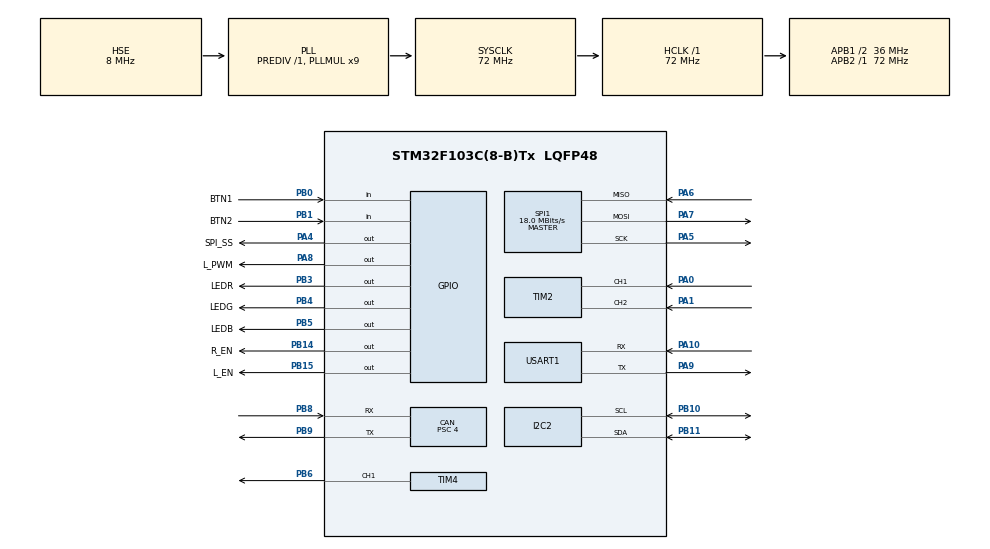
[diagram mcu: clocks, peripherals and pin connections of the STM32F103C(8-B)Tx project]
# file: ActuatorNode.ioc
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CAN.BS1=CAN_BS1_13TQ
CAN.BS2=CAN_BS2_4TQ
CAN.CalculateBaudRate=500000
CAN.CalculateTimeBit=2000
CAN.CalculateTimeQuantum=111.11111111111111
CAN.Prescaler=4
CAN.SJW=CAN_SJW_2TQ
Mcu.Family=STM32F1
Mcu.Name=STM32F103C(8-B)Tx
Mcu.Package=LQFP48
NVIC.CAN1_RX1_IRQn=true\:0\:0\:false\:false\:true\:true\:true\:true
NVIC.PriorityGroup=NVIC_PRIORITYGROUP_4
NVIC.USB_LP_CAN1_RX0_IRQn=true\:0\:0\:false\:false\:true\:true\:true\:true
PA0-WKUP.Signal=S_TIM2_CH1_ETR
PA1.Signal=S_TIM2_CH2
PA10.Mode=Asynchronous
PA10.Signal=USART1_RX
PA4.GPIO_Label=SPI_SS
PA4.Signal=GPIO_Output
PA5.Mode=Full_Duplex_Master
PA5.Signal=SPI1_SCK
PA6.Mode=Full_Duplex_Master
PA6.Signal=SPI1_MISO
PA7.Mode=Full_Duplex_Master
PA7.Signal=SPI1_MOSI
PA8.GPIO_Label=L_PWM
PA8.Signal=GPIO_Output
PA9.Mode=Asynchronous
PA9.Signal=USART1_TX
PB0.GPIO_Label=BTN1
PB0.Signal=GPIO_Input
PB1.GPIO_Label=BTN2
PB1.Signal=GPIO_Input
PB10.Mode=I2C
PB10.Signal=I2C2_SCL
PB11.Mode=I2C
PB11.Signal=I2C2_SDA
PB14.GPIO_Label=R_EN
PB14.Signal=GPIO_Output
PB15.GPIO_Label=L_EN
PB15.Signal=GPIO_Output
PB3.GPIO_Label=LEDR
PB3.PinState=GPIO_PIN_SET
PB3.Signal=GPIO_Output
PB4.GPIO_Label=LEDG
PB4.PinState=GPIO_PIN_SET
PB4.Signal=GPIO_Output
PB5.GPIO_Label=LEDB
PB5.PinState=GPIO_PIN_SET
PB5.Signal=GPIO_Output
PB6.Signal=S_TIM4_CH1
PB8.Mode=CAN_Activate
PB8.Signal=CAN_RX
PB9.Mode=CAN_Activate
PB9.Signal=CAN_TX
PD0-OSC_IN.Mode=HSE-External-Oscillator
PD0-OSC_IN.Signal=RCC_OSC_IN
PD1-OSC_OUT.Mode=HSE-External-Oscillator
PD1-OSC_OUT.Signal=RCC_OSC_OUT
ProjectManager.HeapSize=0x200
ProjectManager.StackSize=0x400
ProjectManager.TargetToolchain=STM32CubeIDE
RCC.AHBFreq_Value=72000000
RCC.APB1CLKDivider=RCC_HCLK_DIV2
RCC.APB1Freq_Value=36000000
RCC.APB1TimFreq_Value=72000000
RCC.APB2Freq_Value=72000000
RCC.APB2TimFreq_Value=72000000
RCC.HCLKFreq_Value=72000000
RCC.PLLMUL=RCC_PLL_MUL9
RCC.PLLSourceVirtual=RCC_PLLSOURCE_HSE
RCC.SYSCLKFreq_VALUE=72000000
RCC.SYSCLKSource=RCC_SYSCLKSOURCE_PLLCLK
RCC.USBFreq_Value=72000000
SH.S_TIM2_CH1_ETR.0=TIM2_CH1,Encoder_Interface
SH.S_TIM2_CH2.0=TIM2_CH2,Encoder_Interface
SH.S_TIM4_CH1.0=TIM4_CH1,PWM Generation1 CH1
SPI1.BaudRatePrescaler=SPI_BAUDRATEPRESCALER_4
SPI1.CalculateBaudRate=18.0 MBits/s
SPI1.Direction=SPI_DIRECTION_2LINES
SPI1.Mode=SPI_MODE_MASTER
SPI1.VirtualType=VM_MASTER
TIM3.Period=199
TIM3.Prescaler=35999
TIM4.Channel-PWM\ Generation1\ CH1=TIM_CHANNEL_1
USART1.VirtualMode=VM_ASYNC
VP_TIM3_VS_ClockSourceINT.Mode=Internal
board=custom

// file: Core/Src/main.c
/* USER CODE BEGIN Header */
/**
  ******************************************************************************
  * @file           : main.c
  * @brief          : Main program body
  ******************************************************************************
  * @attention
  *
  * Copyright (c) 2023 STMicroelectronics.
  * All rights reserved.
  *
  * This software is licensed under terms that can be found in the LICENSE file
  * in the root directory of this software component.
  * If no LICENSE file comes with this software, it is provided AS-IS.
  *
  ******************************************************************************
  */
/* USER CODE END Header */
#include "main.h"

/* USER CODE BEGIN Includes */
#include "gpio.h"
#include "timer.h"
#include "uart.h"
/* USER CODE END Includes */

CAN_HandleTypeDef hcan;

I2C_HandleTypeDef hi2c2;

SPI_HandleTypeDef hspi1;

TIM_HandleTypeDef htim2;
TIM_HandleTypeDef htim3;
TIM_HandleTypeDef htim4;

UART_HandleTypeDef huart1;

void SystemClock_Config(void);
static void MX_GPIO_Init(void);
static void MX_I2C2_Init(void);
static void MX_SPI1_Init(void);
static void MX_TIM2_Init(void);
static void MX_TIM3_Init(void);
static void MX_TIM4_Init(void);
static void MX_USART1_UART_Init(void);
static void MX_CAN_Init(void);

int main(void)
{

  /* MCU Configuration--------------------------------------------------------*/

  /* Reset of all peripherals, Initializes the Flash interface and the Systick. */
  HAL_Init();

  /* Configure the system clock */
  SystemClock_Config();

  /* Initialize all configured peripherals */
  MX_GPIO_Init();
  MX_I2C2_Init();
  MX_SPI1_Init();
  MX_TIM2_Init();
  MX_TIM3_Init();
  MX_TIM4_Init();
  MX_USART1_UART_Init();
  MX_CAN_Init();
  /* USER CODE BEGIN 2 */
  HAL_TIM_Base_Start_IT(&htim3);
  printf("Actuator\n");
  /* USER CODE END 2 */

  /* Infinite loop */
  /* USER CODE BEGIN WHILE */
    while (1)
    {
	    /* blink LED effect current mode */
	    LED_Blink_Mode[LED_Blink_Current_Mode]();
      Buttons_Check();
    /* USER CODE END WHILE */

    }
}

void SystemClock_Config(void)
{
  RCC_OscInitTypeDef RCC_OscInitStruct = {0};
  RCC_ClkInitTypeDef RCC_ClkInitStruct = {0};

  /** Initializes the RCC Oscillators according to the specified parameters
  * in the RCC_OscInitTypeDef structure.
  */
  RCC_OscInitStruct.OscillatorType = RCC_OSCILLATORTYPE_HSE;
  RCC_OscInitStruct.HSEState = RCC_HSE_ON;
  RCC_OscInitStruct.HSEPredivValue = RCC_HSE_PREDIV_DIV1;
  RCC_OscInitStruct.HSIState = RCC_HSI_ON;
  RCC_OscInitStruct.PLL.PLLState = RCC_PLL_ON;
  RCC_OscInitStruct.PLL.PLLSource = RCC_PLLSOURCE_HSE;
  RCC_OscInitStruct.PLL.PLLMUL = RCC_PLL_MUL9;
  if (HAL_RCC_OscConfig(&RCC_OscInitStruct) != HAL_OK)
  {
    Error_Handler();
  }

  /** Initializes the CPU, AHB and APB buses clocks
  */
  RCC_ClkInitStruct.ClockType = RCC_CLOCKTYPE_HCLK|RCC_CLOCKTYPE_SYSCLK
                              |RCC_CLOCKTYPE_PCLK1|RCC_CLOCKTYPE_PCLK2;
  RCC_ClkInitStruct.SYSCLKSource = RCC_SYSCLKSOURCE_PLLCLK;
  RCC_ClkInitStruct.AHBCLKDivider = RCC_SYSCLK_DIV1;
  RCC_ClkInitStruct.APB1CLKDivider = RCC_HCLK_DIV2;
  RCC_ClkInitStruct.APB2CLKDivider = RCC_HCLK_DIV1;

  if (HAL_RCC_ClockConfig(&RCC_ClkInitStruct, FLASH_LATENCY_2) != HAL_OK)
  {
    Error_Handler();
  }
}

static void MX_CAN_Init(void)
{

  hcan.Instance = CAN1;
  hcan.Init.Prescaler = 4;
  hcan.Init.Mode = CAN_MODE_NORMAL;
  hcan.Init.SyncJumpWidth = CAN_SJW_2TQ;
  hcan.Init.TimeSeg1 = CAN_BS1_13TQ;
  hcan.Init.TimeSeg2 = CAN_BS2_4TQ;
  hcan.Init.TimeTriggeredMode = DISABLE;
  hcan.Init.AutoBusOff = DISABLE;
  hcan.Init.AutoWakeUp = DISABLE;
  hcan.Init.AutoRetransmission = DISABLE;
  hcan.Init.ReceiveFifoLocked = DISABLE;
  hcan.Init.TransmitFifoPriority = DISABLE;
  if (HAL_CAN_Init(&hcan) != HAL_OK)
  {
    Error_Handler();
  }
  /* USER CODE BEGIN CAN_Init 2 */
//  CAN_FilterTypeDef canfilterconfig;
//
//  canfilterconfig.FilterActivation = CAN_FILTER_ENABLE;
//  canfilterconfig.FilterBank = 18;  // which filter bank to use from the assigned ones
//  canfilterconfig.FilterFIFOAssignment = CAN_FILTER_FIFO0;
//  canfilterconfig.FilterIdHigh = 0x446<<5;
//  canfilterconfig.FilterIdLow = 0;
//  canfilterconfig.FilterMaskIdHigh = 0x446<<5;
//  canfilterconfig.FilterMaskIdLow = 0x0000;
//  canfilterconfig.FilterMode = CAN_FILTERMODE_IDMASK;
//  canfilterconfig.FilterScale = CAN_FILTERSCALE_32BIT;
//  canfilterconfig.SlaveStartFilterBank = 20;  // how many filters to assign to the CAN1 (master can)
//
//  HAL_CAN_ConfigFilter(&hcan1, &canfilterconfig);
  /* USER CODE END CAN_Init 2 */

}

static void MX_I2C2_Init(void)
{

  hi2c2.Instance = I2C2;
  hi2c2.Init.ClockSpeed = 100000;
  hi2c2.Init.DutyCycle = I2C_DUTYCYCLE_2;
  hi2c2.Init.OwnAddress1 = 0;
  hi2c2.Init.AddressingMode = I2C_ADDRESSINGMODE_7BIT;
  hi2c2.Init.DualAddressMode = I2C_DUALADDRESS_DISABLE;
  hi2c2.Init.OwnAddress2 = 0;
  hi2c2.Init.GeneralCallMode = I2C_GENERALCALL_DISABLE;
  hi2c2.Init.NoStretchMode = I2C_NOSTRETCH_DISABLE;
  if (HAL_I2C_Init(&hi2c2) != HAL_OK)
  {
    Error_Handler();
  }

}

static void MX_SPI1_Init(void)
{

  /* SPI1 parameter configuration*/
  hspi1.Instance = SPI1;
  hspi1.Init.Mode = SPI_MODE_MASTER;
  hspi1.Init.Direction = SPI_DIRECTION_2LINES;
  hspi1.Init.DataSize = SPI_DATASIZE_8BIT;
  hspi1.Init.CLKPolarity = SPI_POLARITY_LOW;
  hspi1.Init.CLKPhase = SPI_PHASE_1EDGE;
  hspi1.Init.NSS = SPI_NSS_SOFT;
  hspi1.Init.BaudRatePrescaler = SPI_BAUDRATEPRESCALER_4;
  hspi1.Init.FirstBit = SPI_FIRSTBIT_MSB;
  hspi1.Init.TIMode = SPI_TIMODE_DISABLE;
  hspi1.Init.CRCCalculation = SPI_CRCCALCULATION_DISABLE;
  hspi1.Init.CRCPolynomial = 10;
  if (HAL_SPI_Init(&hspi1) != HAL_OK)
  {
    Error_Handler();
  }

}

static void MX_TIM2_Init(void)
{

  TIM_Encoder_InitTypeDef sConfig = {0};
  TIM_MasterConfigTypeDef sMasterConfig = {0};

  htim2.Instance = TIM2;
  htim2.Init.Prescaler = 0;
  htim2.Init.CounterMode = TIM_COUNTERMODE_UP;
  htim2.Init.Period = 65535;
  htim2.Init.ClockDivision = TIM_CLOCKDIVISION_DIV1;
  htim2.Init.AutoReloadPreload = TIM_AUTORELOAD_PRELOAD_DISABLE;
  sConfig.EncoderMode = TIM_ENCODERMODE_TI1;
  sConfig.IC1Polarity = TIM_ICPOLARITY_RISING;
  sConfig.IC1Selection = TIM_ICSELECTION_DIRECTTI;
  sConfig.IC1Prescaler = TIM_ICPSC_DIV1;
  sConfig.IC1Filter = 0;
  sConfig.IC2Polarity = TIM_ICPOLARITY_RISING;
  sConfig.IC2Selection = TIM_ICSELECTION_DIRECTTI;
  sConfig.IC2Prescaler = TIM_ICPSC_DIV1;
  sConfig.IC2Filter = 0;
  if (HAL_TIM_Encoder_Init(&htim2, &sConfig) != HAL_OK)
  {
    Error_Handler();
  }
  sMasterConfig.MasterOutputTrigger = TIM_TRGO_RESET;
  sMasterConfig.MasterSlaveMode = TIM_MASTERSLAVEMODE_DISABLE;
  if (HAL_TIMEx_MasterConfigSynchronization(&htim2, &sMasterConfig) != HAL_OK)
  {
    Error_Handler();
  }

}

static void MX_TIM3_Init(void)
{

  TIM_ClockConfigTypeDef sClockSourceConfig = {0};
  TIM_MasterConfigTypeDef sMasterConfig = {0};

  htim3.Instance = TIM3;
  htim3.Init.Prescaler = 35999;
  htim3.Init.CounterMode = TIM_COUNTERMODE_UP;
  htim3.Init.Period = 199;
  htim3.Init.ClockDivision = TIM_CLOCKDIVISION_DIV1;
  htim3.Init.AutoReloadPreload = TIM_AUTORELOAD_PRELOAD_DISABLE;
  if (HAL_TIM_Base_Init(&htim3) != HAL_OK)
  {
    Error_Handler();
  }
  sClockSourceConfig.ClockSource = TIM_CLOCKSOURCE_INTERNAL;
  if (HAL_TIM_ConfigClockSource(&htim3, &sClockSourceConfig) != HAL_OK)
  {
    Error_Handler();
  }
  sMasterConfig.MasterOutputTrigger = TIM_TRGO_RESET;
  sMasterConfig.MasterSlaveMode = TIM_MASTERSLAVEMODE_DISABLE;
  if (HAL_TIMEx_MasterConfigSynchronization(&htim3, &sMasterConfig) != HAL_OK)
  {
    Error_Handler();
  }

}

static void MX_TIM4_Init(void)
{

  TIM_MasterConfigTypeDef sMasterConfig = {0};
  TIM_OC_InitTypeDef sConfigOC = {0};

  htim4.Instance = TIM4;
  htim4.Init.Prescaler = 0;
  htim4.Init.CounterMode = TIM_COUNTERMODE_UP;
  htim4.Init.Period = 65535;
  htim4.Init.ClockDivision = TIM_CLOCKDIVISION_DIV1;
  htim4.Init.AutoReloadPreload = TIM_AUTORELOAD_PRELOAD_DISABLE;
  if (HAL_TIM_PWM_Init(&htim4) != HAL_OK)
  {
    Error_Handler();
  }
  sMasterConfig.MasterOutputTrigger = TIM_TRGO_RESET;
  sMasterConfig.MasterSlaveMode = TIM_MASTERSLAVEMODE_DISABLE;
  if (HAL_TIMEx_MasterConfigSynchronization(&htim4, &sMasterConfig) != HAL_OK)
  {
    Error_Handler();
  }
  sConfigOC.OCMode = TIM_OCMODE_PWM1;
  sConfigOC.Pulse = 0;
  sConfigOC.OCPolarity = TIM_OCPOLARITY_HIGH;
  sConfigOC.OCFastMode = TIM_OCFAST_DISABLE;
  if (HAL_TIM_PWM_ConfigChannel(&htim4, &sConfigOC, TIM_CHANNEL_1) != HAL_OK)
  {
    Error_Handler();
  }
  HAL_TIM_MspPostInit(&htim4);

}

static void MX_USART1_UART_Init(void)
{

  huart1.Instance = USART1;
  huart1.Init.BaudRate = 115200;
  huart1.Init.WordLength = UART_WORDLENGTH_8B;
  huart1.Init.StopBits = UART_STOPBITS_1;
  huart1.Init.Parity = UART_PARITY_NONE;
  huart1.Init.Mode = UART_MODE_TX_RX;
  huart1.Init.HwFlowCtl = UART_HWCONTROL_NONE;
  huart1.Init.OverSampling = UART_OVERSAMPLING_16;
  if (HAL_UART_Init(&huart1) != HAL_OK)
  {
    Error_Handler();
  }

}

static void MX_GPIO_Init(void)
{
  GPIO_InitTypeDef GPIO_InitStruct = {0};

  /* GPIO Ports Clock Enable */
  __HAL_RCC_GPIOD_CLK_ENABLE();
  __HAL_RCC_GPIOA_CLK_ENABLE();
  __HAL_RCC_GPIOB_CLK_ENABLE();

  /*Configure GPIO pin Output Level */
  HAL_GPIO_WritePin(GPIOA, SPI_SS_Pin|L_PWM_Pin, GPIO_PIN_RESET);

  /*Configure GPIO pin Output Level */
  HAL_GPIO_WritePin(GPIOB, R_EN_Pin|L_EN_Pin, GPIO_PIN_RESET);

  /*Configure GPIO pin Output Level */
  HAL_GPIO_WritePin(GPIOB, LEDR_Pin|LEDG_Pin|LEDB_Pin, GPIO_PIN_SET);

  /*Configure GPIO pins : SPI_SS_Pin L_PWM_Pin */
  GPIO_InitStruct.Pin = SPI_SS_Pin|L_PWM_Pin;
  GPIO_InitStruct.Mode = GPIO_MODE_OUTPUT_PP;
  GPIO_InitStruct.Pull = GPIO_NOPULL;
  GPIO_InitStruct.Speed = GPIO_SPEED_FREQ_LOW;
  HAL_GPIO_Init(GPIOA, &GPIO_InitStruct);

  /*Configure GPIO pins : BTN1_Pin BTN2_Pin */
  GPIO_InitStruct.Pin = BTN1_Pin|BTN2_Pin;
  GPIO_InitStruct.Mode = GPIO_MODE_INPUT;
  GPIO_InitStruct.Pull = GPIO_NOPULL;
  HAL_GPIO_Init(GPIOB, &GPIO_InitStruct);

  /*Configure GPIO pins : R_EN_Pin L_EN_Pin LEDR_Pin LEDG_Pin
                           LEDB_Pin */
  GPIO_InitStruct.Pin = R_EN_Pin|L_EN_Pin|LEDR_Pin|LEDG_Pin
                          |LEDB_Pin;
  GPIO_InitStruct.Mode = GPIO_MODE_OUTPUT_PP;
  GPIO_InitStruct.Pull = GPIO_NOPULL;
  GPIO_InitStruct.Speed = GPIO_SPEED_FREQ_LOW;
  HAL_GPIO_Init(GPIOB, &GPIO_InitStruct);

}

void Error_Handler(void)
{
  __disable_irq();
  while (1)
  {
  }
}
